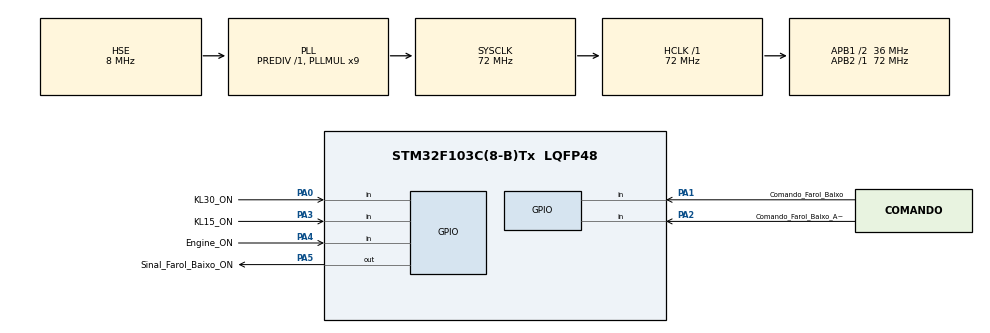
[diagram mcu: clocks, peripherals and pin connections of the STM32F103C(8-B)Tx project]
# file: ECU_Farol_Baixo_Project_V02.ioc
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Mcu.Family=STM32F1
Mcu.Name=STM32F103C(8-B)Tx
Mcu.Package=LQFP48
NVIC.PriorityGroup=NVIC_PRIORITYGROUP_4
PA0-WKUP.GPIO_Label=KL30_ON
PA0-WKUP.GPIO_PuPd=GPIO_PULLDOWN
PA0-WKUP.Signal=GPIO_Input
PA1.GPIO_Label=Comando_Farol_Baixo
PA1.GPIO_PuPd=GPIO_PULLDOWN
PA1.Signal=GPIO_Input
PA2.GPIO_Label=Comando_Farol_Baixo_Automatico
PA2.GPIO_PuPd=GPIO_PULLDOWN
PA2.Signal=GPIO_Input
PA3.GPIO_Label=KL15_ON
PA3.GPIO_PuPd=GPIO_PULLDOWN
PA3.Signal=GPIO_Input
PA4.GPIO_Label=Engine_ON
PA4.GPIO_PuPd=GPIO_PULLDOWN
PA4.Signal=GPIO_Input
PA5.GPIO_Label=Sinal_Farol_Baixo_ON
PA5.Signal=GPIO_Output
PD0-OSC_IN.Mode=HSE-External-Oscillator
PD0-OSC_IN.Signal=RCC_OSC_IN
PD1-OSC_OUT.Mode=HSE-External-Oscillator
PD1-OSC_OUT.Signal=RCC_OSC_OUT
ProjectManager.HeapSize=0x200
ProjectManager.StackSize=0x400
ProjectManager.TargetToolchain=STM32CubeIDE
RCC.AHBFreq_Value=72000000
RCC.APB1CLKDivider=RCC_HCLK_DIV2
RCC.APB1Freq_Value=36000000
RCC.APB1TimFreq_Value=72000000
RCC.APB2Freq_Value=72000000
RCC.APB2TimFreq_Value=72000000
RCC.HCLKFreq_Value=72000000
RCC.PLLMUL=RCC_PLL_MUL9
RCC.PLLSourceVirtual=RCC_PLLSOURCE_HSE
RCC.SYSCLKFreq_VALUE=72000000
RCC.SYSCLKSource=RCC_SYSCLKSOURCE_PLLCLK
RCC.USBFreq_Value=72000000
VP_SYS_VS_ND.Mode=No_Debug
board=custom

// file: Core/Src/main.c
/* USER CODE BEGIN Header */
/**
  ******************************************************************************
  * @file           : main.c
  * @brief          : Main program body
  ******************************************************************************
  * @attention
  *
  * Copyright (c) 2025 STMicroelectronics.
  * All rights reserved.
  *
  * This software is licensed under terms that can be found in the LICENSE file
  * in the root directory of this software component.
  * If no LICENSE file comes with this software, it is provided AS-IS.
  *
  ******************************************************************************
  */
/* USER CODE END Header */
#include "main.h"

void SystemClock_Config(void);
static void MX_GPIO_Init(void);

int main(void)
{

  /* MCU Configuration--------------------------------------------------------*/

  /* Reset of all peripherals, Initializes the Flash interface and the Systick. */
  HAL_Init();

  /* Configure the system clock */
  SystemClock_Config();

  /* Initialize all configured peripherals */
  MX_GPIO_Init();

  /* Infinite loop */
  while (1)
  {

    /* USER CODE BEGIN 3 */
	  // Ler o estado de cada pino de entrada
	  	      GPIO_PinState kl30_on = HAL_GPIO_ReadPin(KL30_ON_GPIO_Port, KL30_ON_Pin);
	  	      GPIO_PinState comando_manual = HAL_GPIO_ReadPin(Comando_Farol_Baixo_GPIO_Port, Comando_Farol_Baixo_Pin);
	  	      GPIO_PinState comando_automatico = HAL_GPIO_ReadPin(Comando_Farol_Baixo_Automatico_GPIO_Port, Comando_Farol_Baixo_Automatico_Pin);
	  	      GPIO_PinState kl15_on = HAL_GPIO_ReadPin(KL15_ON_GPIO_Port, KL15_ON_Pin);
	  	      GPIO_PinState engine_on = HAL_GPIO_ReadPin(Engine_ON_GPIO_Port, Engine_ON_Pin);

	  	      // Implementar a lógica
	  	      GPIO_PinState comando_geral = (comando_manual == GPIO_PIN_SET || comando_automatico == GPIO_PIN_SET);
	  	      GPIO_PinState status_veiculo = (kl15_on == GPIO_PIN_SET || engine_on == GPIO_PIN_SET);

	  	      GPIO_PinState sinal_farol_baixo_on;

	  	      if (kl30_on == GPIO_PIN_SET && comando_geral && status_veiculo)
	  	      {
	  	        sinal_farol_baixo_on = GPIO_PIN_SET; // Farol Baixo Ligado
	  	      }
	  	      else
	  	      {
	  	        sinal_farol_baixo_on = GPIO_PIN_RESET; // Farol Baixo Desligado
	  	      }

	  	      // Escrever o estado final no pino de saída
	  	      HAL_GPIO_WritePin(Sinal_Farol_Baixo_ON_GPIO_Port, Sinal_Farol_Baixo_ON_Pin, sinal_farol_baixo_on);
  }
  /* USER CODE END 3 */
}

void SystemClock_Config(void)
{
  RCC_OscInitTypeDef RCC_OscInitStruct = {0};
  RCC_ClkInitTypeDef RCC_ClkInitStruct = {0};

  /** Initializes the RCC Oscillators according to the specified parameters
  * in the RCC_OscInitTypeDef structure.
  */
  RCC_OscInitStruct.OscillatorType = RCC_OSCILLATORTYPE_HSE;
  RCC_OscInitStruct.HSEState = RCC_HSE_ON;
  RCC_OscInitStruct.HSEPredivValue = RCC_HSE_PREDIV_DIV1;
  RCC_OscInitStruct.HSIState = RCC_HSI_ON;
  RCC_OscInitStruct.PLL.PLLState = RCC_PLL_ON;
  RCC_OscInitStruct.PLL.PLLSource = RCC_PLLSOURCE_HSE;
  RCC_OscInitStruct.PLL.PLLMUL = RCC_PLL_MUL9;
  if (HAL_RCC_OscConfig(&RCC_OscInitStruct) != HAL_OK)
  {
    Error_Handler();
  }

  /** Initializes the CPU, AHB and APB buses clocks
  */
  RCC_ClkInitStruct.ClockType = RCC_CLOCKTYPE_HCLK|RCC_CLOCKTYPE_SYSCLK
                              |RCC_CLOCKTYPE_PCLK1|RCC_CLOCKTYPE_PCLK2;
  RCC_ClkInitStruct.SYSCLKSource = RCC_SYSCLKSOURCE_PLLCLK;
  RCC_ClkInitStruct.AHBCLKDivider = RCC_SYSCLK_DIV1;
  RCC_ClkInitStruct.APB1CLKDivider = RCC_HCLK_DIV2;
  RCC_ClkInitStruct.APB2CLKDivider = RCC_HCLK_DIV1;

  if (HAL_RCC_ClockConfig(&RCC_ClkInitStruct, FLASH_LATENCY_2) != HAL_OK)
  {
    Error_Handler();
  }
}

static void MX_GPIO_Init(void)
{
  GPIO_InitTypeDef GPIO_InitStruct = {0};

  /* GPIO Ports Clock Enable */
  __HAL_RCC_GPIOD_CLK_ENABLE();
  __HAL_RCC_GPIOA_CLK_ENABLE();

  /*Configure GPIO pin Output Level */
  HAL_GPIO_WritePin(Sinal_Farol_Baixo_ON_GPIO_Port, Sinal_Farol_Baixo_ON_Pin, GPIO_PIN_RESET);

  /*Configure GPIO pins : KL30_ON_Pin Comando_Farol_Baixo_Pin Comando_Farol_Baixo_Automatico_Pin KL15_ON_Pin
                           Engine_ON_Pin */
  GPIO_InitStruct.Pin = KL30_ON_Pin|Comando_Farol_Baixo_Pin|Comando_Farol_Baixo_Automatico_Pin|KL15_ON_Pin
                          |Engine_ON_Pin;
  GPIO_InitStruct.Mode = GPIO_MODE_INPUT;
  GPIO_InitStruct.Pull = GPIO_PULLDOWN;
  HAL_GPIO_Init(GPIOA, &GPIO_InitStruct);

  /*Configure GPIO pin : Sinal_Farol_Baixo_ON_Pin */
  GPIO_InitStruct.Pin = Sinal_Farol_Baixo_ON_Pin;
  GPIO_InitStruct.Mode = GPIO_MODE_OUTPUT_PP;
  GPIO_InitStruct.Pull = GPIO_NOPULL;
  GPIO_InitStruct.Speed = GPIO_SPEED_FREQ_LOW;
  HAL_GPIO_Init(Sinal_Farol_Baixo_ON_GPIO_Port, &GPIO_InitStruct);

}

void Error_Handler(void)
{
  __disable_irq();
  while (1)
  {
  }
}
